VERSION ""

NS_ :

BS_:

BU_: ECU1

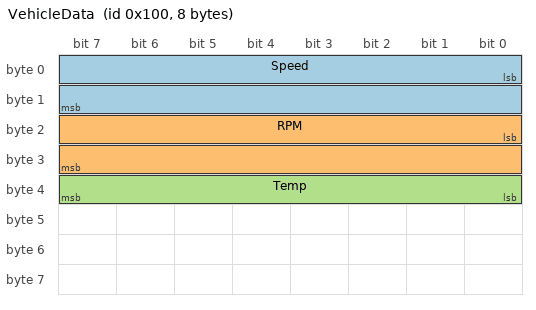
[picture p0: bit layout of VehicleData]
BO_ 256 VehicleData: 8 ECU1

SG_ Speed : 0|16@1+ (1,0) [0|250] "kmph" ECU1
SG_ RPM : 16|16@1+ (1,0) [0|8000] "rpm" ECU1
SG_ Temp : 32|8@1- (1,0) [-40|215] "degC" ECU1

BO_ 512 EngineData: 8 ECU1

 SG_ Speed : 0|8@1+ (1,0) [0|200] "kmph" ECU1
 SG_ RPM : 8|16@1+ (0.5,1) [0|8000] "rpm" ECU1

BO_ 2566848768 MeraInfo: 8 ECU1

 SG_ Speed : 0|16@1+ (1,0) [0|300] "kmph" ECU1
 SG_ RPM : 16|16@1+ (1,0) [0|8000] "rpm" ECU1

BO_ 2634006946 BatteryData: 8 ECU1
 SG_ throttle : 0|16@1+ (1,0) [0|400] "%" ECU1
 SG_ Acceleration : 16|16@1+ (1,0) [0|300] "kmph^2" ECU1

BO_ 2634014976 GearboxData: 8 ECU1
 SG_ Speed : 0|16@1+ (1,0) [0|300] "kmph" ECU1
 SG_ RPM : 16|16@1+ (1,0) [0|8000] "rpm" ECU1

BO_ 2634015232 TransmissionData: 8 ECU1
 SG_ Speed : 0|16@1+ (1,0) [0|300] "kmph" ECU1
 SG_ RPM : 16|16@1+ (1,0) [0|8000] "rpm" ECU1

BO_ 2634015488 DrivelineData: 8 ECU1
 SG_ Speed : 0|16@1+ (1,0) [0|300] "kmph" ECU1
 SG_ RPM : 16|16@1+ (1,0) [0|8000] "rpm" ECU1

BO_ 512 EngineDataFD: 32 ECU1
 SG_ RPM : 0|16@1+ (1,0) [0|65535] "rpm" ECU1
 SG_ Speed : 16|16@1+ (0.1,0) [0|300] "km/h" ECU1
 SG_ Temp : 32|8@1+ (1,-40) [-40|215] "C" ECU1
